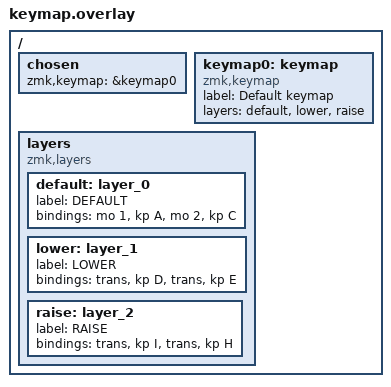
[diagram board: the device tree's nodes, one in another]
#include <behaviors.dtsi>
#include <dt-bindings/zmk/keys.h>

/ {
	chosen {
		zmk,keymap = &keymap0;
	};
	keymap0: keymap {
		compatible = "zmk,keymap";
		label ="Default keymap";
		layers = <&default &lower &raise>;
	};

	layers {
		compatible = "zmk,layers";

		default: layer_0 {
			label = "DEFAULT";

			bindings = <
				&mo 1 &kp A
				&mo 2 &kp C>;
		};

		lower: layer_1 {
			label = "LOWER";

			bindings = <
				&trans &kp D
				&trans &kp E>;
		};

		raise: layer_2 {
			label = "RAISE";

			bindings = <
				&trans &kp I
				&trans &kp H>;
		};
	};
};
